AUTOSAR XML (schema 4-3-0)
package /PrmM_ArItf
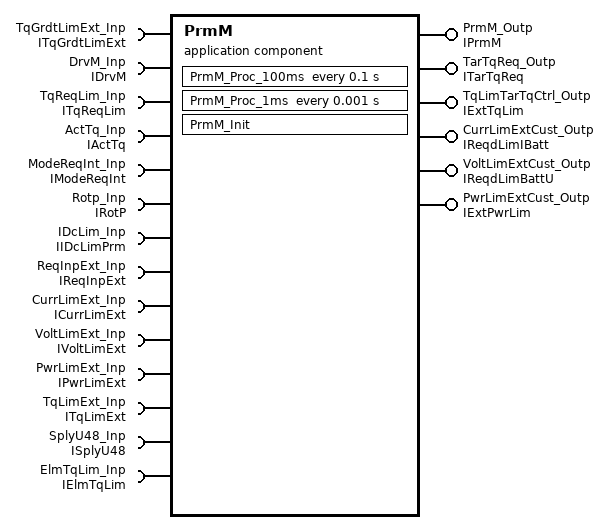
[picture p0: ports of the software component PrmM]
  application sw component type PrmM
    provide port PrmM_Outp: provided-interface=IPrmM
      provided-com-specs:
        data-element=uDcMinAllwd, init-value=24.0
        data-element=mMaxTqGrdtInt, init-value=0.1
        data-element=uDcMaxAllwd, init-value=24.0
    require port TqGrdtLimExt_Inp: nonqueued-receiver-com-spec{data-element=yTqGrdtLimExt, init-value=0}, required-interface=ITqGrdtLimExt
    require port DrvM_Inp: required-com-specs=[{data-element=sStateCAN, init-value=0}, {data-element=sState, init-value=0}], required-interface=IDrvM
    5 x provide port:
      TarTqReq_Outp: provided-interface=ITarTqReq
        provided-com-specs:
          data-element=mReqTqEM, init-value=0
          data-element=nReqdSpdEM, init-value=0
          data-element=uReqUEM, init-value=0
          data-element=xKpSpd, init-value=0
      TqLimTarTqCtrl_Outp: provided-com-specs=[{data-element=mTqLimMax, init-value=0}, {data-element=mTqLimMin, init-value=0}], provided-interface=IExtTqLim
      CurrLimExtCust_Outp: provided-com-specs=[{data-element=iReqdMaxBattI, init-value=0}, {data-element=iReqdMinBattI, init-value=0}], provided-interface=IReqdLimIBatt
      VoltLimExtCust_Outp: provided-com-specs=[{data-element=uReqdMaxBattU, init-value=0}, {data-element=uReqdMinBattU, init-value=0}], provided-interface=IReqdLimBattU
      PwrLimExtCust_Outp: provided-com-specs=[{data-element=pPwrMaxLim, init-value=0}, {data-element=pPwrMinLim, init-value=0}], provided-interface=IExtPwrLim
    12 x require port:
      TqReqLim_Inp: required-interface=ITqReqLim
        required-com-specs:
          data-element=ITqReqLim/mTqMax, init-value=0
          data-element=sStateTqRedn, init-value=0
          data-element=mTqReqLimd, init-value=0
          data-element=ITqReqLim/mTqMin, init-value=0
          data-element=mTqReqGrdtLimd, init-value=0
          data-element=mTqThermLimMin, init-value=0
          data-element=mTqThermLimMax, init-value=0
      ActTq_Inp: required-interface=IActTq
        required-com-specs:
          data-element=mTqActFild, init-value=0
          data-element=mTqDelta, init-value=0
          data-element=mTqAct, init-value=0
          data-element=mDragTq, init-value=0
      ModeReqInt_Inp: nonqueued-receiver-com-spec{data-element=sIntReqMode, init-value=CS_DrvM_STATE_Idle}, required-interface=IModeReqInt
      Rotp_Inp: required-interface=IRotP
        required-com-specs:
          data-element=xSinRaw, init-value=0
          data-element=xCosRaw, init-value=0
          data-element=nSpdMecl, init-value=0
          data-element=wPosnSnsr, init-value=0
          data-element=sStateRaw, init-value=0
          data-element=xSinCorr, init-value=0
          data-element=xCosCorr, init-value=0
          data-element=wPosnElec4, init-value=0
          data-element=wPosnElec3, init-value=0
          data-element=wPosnElec1, init-value=0
          data-element=wPosnElec2, init-value=0
          data-element=tTimestamp, init-value=0
          data-element=nSpdElec, init-value=0
      IDcLim_Inp: required-com-specs=[{data-element=IDcLimMaxInt, init-value=360}, {data-element=IDcLimMinInt, init-value=-290}], required-interface=IIDcLimPrm
      ReqInpExt_Inp: required-interface=IReqInpExt
        required-com-specs:
          data-element=uReqUEMExt, init-value=0
          data-element=mReqTqEMExt, init-value=0
          data-element=nReqSpdEMExt, init-value=0
      CurrLimExt_Inp: required-com-specs=[{data-element=iCurrMinLimExt, init-value=-290}, {data-element=iCurrMaxLimExt, init-value=360}], required-interface=ICurrLimExt
      VoltLimExt_Inp: required-com-specs=[{data-element=uVoltMaxLimExt, init-value=52}, {data-element=uVoltMinLimExt, init-value=24}], required-interface=IVoltLimExt
      PwrLimExt_Inp: required-com-specs=[{data-element=pPwrMInLimExt, init-value=-25000}, {data-element=pPwrMaxLimExt, init-value=25000}], required-interface=IPwrLimExt
      TqLimExt_Inp: required-com-specs=[{data-element=mTqLimMaxExt, init-value=40}, {data-element=mTqLimMinExt, init-value=0}], required-interface=ITqLimExt
      SplyU48_Inp: required-interface=ISplyU48
        required-com-specs:
          data-element=sUb48PlausStateRaw, init-value=0
          data-element=uUb48Ivs, init-value=0
          data-element=sUb48StateRaw, init-value=0
          data-element=uUb48Plaus, init-value=0
          data-element=uPhaseVoltLim, init-value=0
          data-element=uUb48, init-value=0
      ElmTqLim_Inp: required-interface=IElmTqLim
        required-com-specs:
          data-element=iIdqLenTqMax, init-value=0
          data-element=IElmTqLim/mTqMin, init-value=0
          data-element=iIdqLenTqMin, init-value=0
          data-element=IElmTqLim/mTqMax, init-value=0
    behavior PrmM_InternalBehavior: data-type-mapping=[Core_DTyps_DM_PrmM, PrmM_DTyps_DM_PrmM, DrvM_DTyps_DM_PrmM, TarTqC_DTyps_DM_PrmM, ElDern_DTyps_DM_PrmM, VoltLim_DTyps_DM_PrmM, PwrLim_DTyps_DM_PrmM, TqReqLim_DTyps_DM_PrmM, ActTq_DTyps_DM_PrmM, RotP_DTyps_DM_PrmM, ImplementationDataTypes_DM_PrmM, SplyU48_DTyps_DM_PrmM, ElmTqLim_DTyps_DM_PrmM], handle-termination-and-restart=NO-SUPPORT
      init event PrmM_InitEvent: start-on-event=PrmM_Init
      timing event TMT_PrmM_Proc_100ms: start-on-event=PrmM_Proc_100ms, period=0.1
      timing event TMT_PrmM_Proc_1ms: start-on-event=PrmM_Proc_1ms, period=0.001
      explicit-inter-runnable-variables:
        data uDcMin: type=AD_PrmM_tUDCMINALLWD, init-value=24.0
        data uDcMax: type=AD_PrmM_tUDCMAXALLWD, init-value=24.0
      runnable PrmM_Init
      runnable PrmM_Proc_100ms
        data-receive-point-by-arguments:
          access REC_DrvM_Inp_sState: accessed-variable=DrvM_Inp.sState
        written-local-variables:
          access WRITE_uDcMin: accessed-variable=uDcMin
          access WRITE_uDcMax: accessed-variable=uDcMax
      runnable PrmM_Proc_1ms
        data-receive-point-by-arguments:
          20 x access:
            REC_ActTq_Inp_mDragTq: accessed-variable=ActTq_Inp.mDragTq
            REC_TqLimExt_Inp_mTqLimMaxExt: accessed-variable=TqLimExt_Inp.mTqLimMaxExt
            REC_ElmTqLim_Inp_mTqMin: accessed-variable=ElmTqLim_Inp.mTqMin
            REC_TqReqLim_Inp_mTqMax: accessed-variable=TqReqLim_Inp.mTqMax
            REC_TqLimExt_Inp_mTqLimMinExt: accessed-variable=TqLimExt_Inp.mTqLimMinExt
            REC_TqGrdtLimExt_Inp_yTqGrdtLimExt: accessed-variable=TqGrdtLimExt_Inp.yTqGrdtLimExt
            REC_Rotp_Inp_nSpdMecl: accessed-variable=Rotp_Inp.nSpdMecl
            REC_TqReqLim_Inp_mTqMin: accessed-variable=TqReqLim_Inp.mTqMin
            REC_DrvM_Inp_sState: accessed-variable=DrvM_Inp.sState
            REC_SplyU48_Inp_uUb48: accessed-variable=SplyU48_Inp.uUb48
            REC_ModeReqInt_Inp_sIntReqMode: accessed-variable=ModeReqInt_Inp.sIntReqMode
            REC_ReqInpExt_Inp_mReqTqEMExt: accessed-variable=ReqInpExt_Inp.mReqTqEMExt
            REC_ReqInpExt_Inp_uReqUEMExt: accessed-variable=ReqInpExt_Inp.uReqUEMExt
            REC_ReqInpExt_Inp_nReqSpdEMExt: accessed-variable=ReqInpExt_Inp.nReqSpdEMExt
            REC_CurrLimExt_Inp_iCurrMinLimExt: accessed-variable=CurrLimExt_Inp.iCurrMinLimExt
            REC_VoltLimExt_Inp_uVoltMaxLimExt: accessed-variable=VoltLimExt_Inp.uVoltMaxLimExt
            REC_PwrLimExt_Inp_pPwrMInLimExt: accessed-variable=PwrLimExt_Inp.pPwrMInLimExt
            REC_CurrLimExt_Inp_iCurrMaxLimExt: accessed-variable=CurrLimExt_Inp.iCurrMaxLimExt
            REC_PwrLimExt_Inp_pPwrMaxLimExt: accessed-variable=PwrLimExt_Inp.pPwrMaxLimExt
            REC_VoltLimExt_Inp_uVoltMinLimExt: accessed-variable=VoltLimExt_Inp.uVoltMinLimExt
        data-send-points:
          11 x access:
            SEND_TqLimTarTqCtrl_Outp_mTqLimMin: accessed-variable=TqLimTarTqCtrl_Outp.mTqLimMin
            SEND_TqLimTarTqCtrl_Outp_mTqLimMax: accessed-variable=TqLimTarTqCtrl_Outp.mTqLimMax
            SEND_TarTqReq_Outp_nReqdSpdEM: accessed-variable=TarTqReq_Outp.nReqdSpdEM
            SEND_TarTqReq_Outp_uReqUEM: accessed-variable=TarTqReq_Outp.uReqUEM
            SEND_TarTqReq_Outp_mReqTqEM: accessed-variable=TarTqReq_Outp.mReqTqEM
            SEND_VoltLimExtCust_Outp_uReqdMinBattU: accessed-variable=VoltLimExtCust_Outp.uReqdMinBattU
            SEND_CurrLimExtCust_Outp_iReqdMinBattI: accessed-variable=CurrLimExtCust_Outp.iReqdMinBattI
            SEND_CurrLimExtCust_Outp_iReqdMaxBattI: accessed-variable=CurrLimExtCust_Outp.iReqdMaxBattI
            SEND_PwrLimExtCust_Outp_pPwrMinLim: accessed-variable=PwrLimExtCust_Outp.pPwrMinLim
            SEND_VoltLimExtCust_Outp_uReqdMaxBattU: accessed-variable=VoltLimExtCust_Outp.uReqdMaxBattU
            SEND_PwrLimExtCust_Outp_pPwrMaxLim: accessed-variable=PwrLimExtCust_Outp.pPwrMaxLim
        read-local-variables:
          access READ_uDcMax: accessed-variable=uDcMax
          access READ_uDcMin: accessed-variable=uDcMin
  6 x sender receiver interface:
    ITqGrdtLimExt: invalidation-policy{data-element=yTqGrdtLimExt, handle-invalid=DONT-INVALIDATE}
      data yTqGrdtLimExt: type=AD_tYTQGRDTLIMEXT
    IReqInpExt
      data mReqTqEMExt: type=AD_tMREQTQEMEXT
      data nReqSpdEMExt: type=AD_tNREQDSPDEMEXT
      data uReqUEMExt: type=AD_tUREQVOLTEMEXT
      invalidation-policys:
        data-element=mReqTqEMExt, handle-invalid=DONT-INVALIDATE
        data-element=nReqSpdEMExt, handle-invalid=DONT-INVALIDATE
        data-element=uReqUEMExt, handle-invalid=DONT-INVALIDATE
    ICurrLimExt
      data iCurrMinLimExt: type=AD_tICURRMINLIMEXT
      data iCurrMaxLimExt: type=AD_tICURRMAXLIMEXT
      invalidation-policys:
        data-element=iCurrMinLimExt, handle-invalid=DONT-INVALIDATE
        data-element=iCurrMaxLimExt, handle-invalid=DONT-INVALIDATE
    IVoltLimExt
      data uVoltMinLimExt: type=AD_tUVOLTMINLIMEXT
      data uVoltMaxLimExt: type=AD_tUVOLTMAXLIMEXT
      invalidation-policys:
        data-element=uVoltMinLimExt, handle-invalid=DONT-INVALIDATE
        data-element=uVoltMaxLimExt, handle-invalid=DONT-INVALIDATE
    IPwrLimExt
      data pPwrMaxLimExt: type=AD_tPPWRMAXLIMEXT
      data pPwrMInLimExt: type=AD_tPPWRMINLIMEXT
      invalidation-policys:
        data-element=pPwrMaxLimExt, handle-invalid=DONT-INVALIDATE
        data-element=pPwrMInLimExt, handle-invalid=DONT-INVALIDATE
    ITqLimExt
      data mTqLimMaxExt: type=AD_tMTQLIMMAXEXT
      data mTqLimMinExt: type=AD_tMTQLIMMINEXT
      invalidation-policys:
        data-element=mTqLimMaxExt, handle-invalid=DONT-INVALIDATE
        data-element=mTqLimMinExt, handle-invalid=DONT-INVALIDATE
  swc implementation PrmM_Implementation: behavior=PrmM_InternalBehavior
    code-descriptors:
      code Default: artifact-descriptors=autosar-engineering-object={short-label=Default, category=SWSRC}
package /PrmM_ArItf/PrmM_DTyps
  app type AD_tYTQGRDTLIMEXT: category=VALUE, range phys 0..2000  # Unit: Nm/s
  data type mapping set PrmM_DTyps_DM_PrmM
    data-type-maps:
      application-data-type=AD_tYTQGRDTLIMEXT, implementation-data-type=float32
      application-data-type=AD_tMREQTQEMEXT, implementation-data-type=float32
      application-data-type=AD_tNREQDSPDEMEXT, implementation-data-type=float32
      application-data-type=AD_tUREQVOLTEMEXT, implementation-data-type=float32
      application-data-type=AD_tICURRMINLIMEXT, implementation-data-type=float32
      application-data-type=AD_tICURRMAXLIMEXT, implementation-data-type=float32
      application-data-type=AD_tUVOLTMINLIMEXT, implementation-data-type=float32
      application-data-type=AD_tUVOLTMAXLIMEXT, implementation-data-type=float32
      application-data-type=AD_tPPWRMAXLIMEXT, implementation-data-type=float32
      application-data-type=AD_tPPWRMINLIMEXT, implementation-data-type=float32
      application-data-type=AD_tMTQLIMMAXEXT, implementation-data-type=float32
      application-data-type=AD_tMTQLIMMINEXT, implementation-data-type=float32
  app type AD_tMREQTQEMEXT: category=VALUE, range phys -75..75
  app type AD_tNREQDSPDEMEXT: category=VALUE, range phys -10000..55534
  app type AD_tUREQVOLTEMEXT: category=VALUE, range phys 0..60
  app type AD_tICURRMINLIMEXT: category=VALUE, range phys -1200..1200
  app type AD_tICURRMAXLIMEXT: category=VALUE, range phys -1200..1200
  app type AD_tUVOLTMINLIMEXT: category=VALUE, range phys 20..65
  app type AD_tUVOLTMAXLIMEXT: category=VALUE, range phys 20..65
  app type AD_tPPWRMAXLIMEXT: category=VALUE, range phys -16000..16000
  app type AD_tPPWRMINLIMEXT: category=VALUE, range phys -16000..16000
  app type AD_tMTQLIMMAXEXT: category=VALUE, range phys 0..65
  app type AD_tMTQLIMMINEXT: category=VALUE, range phys -65..0
package /ComponentTypes
  sender receiver interface IPrmM
    data uDcMinAllwd: type=AD_PrmM_tUDCMINALLWD
    data uDcMaxAllwd: type=AD_PrmM_tUDCMAXALLWD
    data mMaxTqGrdtInt: type=AD_PrmM_tMMAXTQGRDINT
    invalidation-policys:
      data-element=uDcMinAllwd, handle-invalid=DONT-INVALIDATE
      data-element=uDcMaxAllwd, handle-invalid=DONT-INVALIDATE
      data-element=mMaxTqGrdtInt, handle-invalid=DONT-INVALIDATE
  sender receiver interface IIDcLimPrm
    data IDcLimMinInt: type=AD_tIDCLIMMININT
    data IDcLimMaxInt: type=AD_tIDCLIMMAXINT
    invalidation-policys:
      data-element=IDcLimMinInt, handle-invalid=DONT-INVALIDATE
      data-element=IDcLimMaxInt, handle-invalid=DONT-INVALIDATE
package /ComponentTypes/Core_DTyps
  app type AD_PrmM_tUDCMINALLWD: category=VALUE, range phys 20..65
  data type mapping set Core_DTyps_DM_PrmM
    data-type-maps:
      application-data-type=AD_PrmM_tUDCMINALLWD, implementation-data-type=float32
      application-data-type=AD_PrmM_tUDCMAXALLWD, implementation-data-type=float32
      application-data-type=AD_PrmM_tMMAXTQGRDINT, implementation-data-type=float32
      application-data-type=AD_tIDCLIMMININT, implementation-data-type=float32
      application-data-type=AD_tIDCLIMMAXINT, implementation-data-type=float32
  app type AD_PrmM_tUDCMAXALLWD: category=VALUE, range phys 20..65
  app type AD_PrmM_tMMAXTQGRDINT: category=VALUE, range phys 0.1..2000
  app type AD_tIDCLIMMININT: category=VALUE, range phys -400..0
  app type AD_tIDCLIMMAXINT: category=VALUE, range phys 0..400
package /DrvM_ArItf
  sender receiver interface IDrvM
    data sState: type=AD_DrvM_tSTATEIDX_E
    data sStateCAN: type=AD_DrvM_tSTATEIDX_E
    invalidation-policys:
      data-element=sState, handle-invalid=DONT-INVALIDATE
      data-element=sStateCAN, handle-invalid=DONT-INVALIDATE
  sender receiver interface IModeReqInt: invalidation-policy{data-element=sIntReqMode, handle-invalid=DONT-INVALIDATE}
    data sIntReqMode: type=AD_DrvM_tSTATEIDX_E
package /DrvM_ArItf/DrvM_DTyps
  compu method CM_DrvM_AD_DrvM_tSTATEIDX_E: 0=CS_DrvM_STATE_Idle, 3=CS_DrvM_STATE_Volt, 5=CS_DrvM_STATE_BattDiscnctd
  app type AD_DrvM_tSTATEIDX_E: category=VALUE, compu-method=CM_DrvM_AD_DrvM_tSTATEIDX_E, range raw 0..255
  impl type CS_DrvM_tSTATEIDX_E: compu-method=CM_DrvM_AD_DrvM_tSTATEIDX_E, implementation-data-type=uint8
  data type mapping set DrvM_DTyps_DM_PrmM: data-type-map{application-data-type=AD_DrvM_tSTATEIDX_E, implementation-data-type=CS_DrvM_tSTATEIDX_E}
package /TarTqC_ArItf
  sender receiver interface ITarTqReq
    4 x data:
      uReqUEM: type=AD_ComWrp_tUREQVOLTEM
      mReqTqEM: type=AD_ComWrp_tMREQTQEM
      nReqdSpdEM: type=AD_ComWrp_tNREQDSPDEM
      xKpSpd: type=AD_ComWrp_tXKPSPD
    invalidation-policys:
      data-element=uReqUEM, handle-invalid=DONT-INVALIDATE
      data-element=mReqTqEM, handle-invalid=DONT-INVALIDATE
      data-element=nReqdSpdEM, handle-invalid=DONT-INVALIDATE
      data-element=xKpSpd, handle-invalid=DONT-INVALIDATE
  sender receiver interface IExtTqLim
    data mTqLimMax: type=AD_ComWrp_tMTQLIMMAX
    data mTqLimMin: type=AD_ComWrp_tMTQLIMMIN
    invalidation-policys:
      data-element=mTqLimMax, handle-invalid=DONT-INVALIDATE
      data-element=mTqLimMin, handle-invalid=DONT-INVALIDATE
package /TarTqC_ArItf/TarTqC_DTyps
  app type AD_ComWrp_tUREQVOLTEM: category=VALUE, range phys 0..60
  data type mapping set TarTqC_DTyps_DM_PrmM
    data-type-maps:
      application-data-type=AD_ComWrp_tUREQVOLTEM, implementation-data-type=float32
      application-data-type=AD_ComWrp_tMREQTQEM, implementation-data-type=float32
      application-data-type=AD_ComWrp_tNREQDSPDEM, implementation-data-type=float32
      application-data-type=AD_ComWrp_tXKPSPD, implementation-data-type=float32
      application-data-type=AD_ComWrp_tMTQLIMMAX, implementation-data-type=float32
      application-data-type=AD_ComWrp_tMTQLIMMIN, implementation-data-type=float32
  app type AD_ComWrp_tMREQTQEM: category=VALUE, range phys -75..75
  app type AD_ComWrp_tNREQDSPDEM: category=VALUE, range phys -10000..55534
  app type AD_ComWrp_tXKPSPD: category=VALUE, range phys -4..3.984375
  app type AD_ComWrp_tMTQLIMMAX: category=VALUE, range phys -75..75
  app type AD_ComWrp_tMTQLIMMIN: category=VALUE, range phys -75..75
package /ElDern_ArItf
  sender receiver interface IReqdLimIBatt
    data iReqdMinBattI: type=AD_ComWrp_tIREQDMINBATTI
    data iReqdMaxBattI: type=AD_ComWrp_tIREQDMAXBATTI
    invalidation-policys:
      data-element=iReqdMinBattI, handle-invalid=DONT-INVALIDATE
      data-element=iReqdMaxBattI, handle-invalid=DONT-INVALIDATE
package /ElDern_ArItf/ElDern_DTyps
  app type AD_ComWrp_tIREQDMINBATTI: category=VALUE, range phys -1200..1200
  data type mapping set ElDern_DTyps_DM_PrmM
    data-type-maps:
      application-data-type=AD_ComWrp_tIREQDMINBATTI, implementation-data-type=float32
      application-data-type=AD_ComWrp_tIREQDMAXBATTI, implementation-data-type=float32
  app type AD_ComWrp_tIREQDMAXBATTI: category=VALUE, range phys -1200..1200
package /VoltLim_ArItf
  sender receiver interface IReqdLimBattU
    data uReqdMinBattU: type=AD_ComWrp_tUREQDMINBATTU
    data uReqdMaxBattU: type=AD_ComWrp_tUREQDMAXBATTU
    invalidation-policys:
      data-element=uReqdMinBattU, handle-invalid=DONT-INVALIDATE
      data-element=uReqdMaxBattU, handle-invalid=DONT-INVALIDATE
package /VoltLim_ArItf/VoltLim_DTyps
  app type AD_ComWrp_tUREQDMINBATTU: category=VALUE, range phys 0..2500
  data type mapping set VoltLim_DTyps_DM_PrmM
    data-type-maps:
      application-data-type=AD_ComWrp_tUREQDMINBATTU, implementation-data-type=float32
      application-data-type=AD_ComWrp_tUREQDMAXBATTU, implementation-data-type=float32
  app type AD_ComWrp_tUREQDMAXBATTU: category=VALUE, range phys 0..2500
package /PwrLim_ArItf
  sender receiver interface IExtPwrLim
    data pPwrMaxLim: type=AD_ComWrp_tPPWRMAXLIM
    data pPwrMinLim: type=AD_ComWrp_tPPWRMINLIM
    invalidation-policys:
      data-element=pPwrMaxLim, handle-invalid=DONT-INVALIDATE
      data-element=pPwrMinLim, handle-invalid=DONT-INVALIDATE
package /PwrLim_ArItf/PwrLim_DTyps
  app type AD_ComWrp_tPPWRMAXLIM: category=VALUE, range phys -819000..819200
  data type mapping set PwrLim_DTyps_DM_PrmM
    data-type-maps:
      application-data-type=AD_ComWrp_tPPWRMAXLIM, implementation-data-type=float32
      application-data-type=AD_ComWrp_tPPWRMINLIM, implementation-data-type=float32
  app type AD_ComWrp_tPPWRMINLIM: category=VALUE, range phys -819000..819200
package /TqReqLim_ArItf
  sender receiver interface ITqReqLim
    7 x data:
      mTqThermLimMax: type=AD_TqReqLim_tTQTHERMLIMMAX
      mTqMax: type=AD_TqReqLim_tMTQMAX
      mTqReqGrdtLimd: type=AD_TqReqLim_tMTQGRDLIMD
      mTqMin: type=AD_TqReqLim_tMTQMIN
      mTqThermLimMin: type=AD_TqReqLim_tTQTHERMLIMMIN
      sStateTqRedn: type=AD_TqReqLim_tSTATETQREDN_E
      mTqReqLimd: type=AD_TqReqLim_tMTQLIMD
    invalidation-policys:
      data-element=mTqThermLimMax, handle-invalid=DONT-INVALIDATE
      data-element=ITqReqLim/mTqMax, handle-invalid=DONT-INVALIDATE
      data-element=mTqReqGrdtLimd, handle-invalid=DONT-INVALIDATE
      data-element=ITqReqLim/mTqMin, handle-invalid=DONT-INVALIDATE
      data-element=mTqThermLimMin, handle-invalid=DONT-INVALIDATE
      data-element=sStateTqRedn, handle-invalid=DONT-INVALIDATE
      data-element=mTqReqLimd, handle-invalid=DONT-INVALIDATE
package /TqReqLim_ArItf/TqReqLim_DTyps
  app type AD_TqReqLim_tTQTHERMLIMMAX: category=VALUE, range phys 0..85
  data type mapping set TqReqLim_DTyps_DM_PrmM
    data-type-maps:
      application-data-type=AD_TqReqLim_tTQTHERMLIMMAX, implementation-data-type=float32
      application-data-type=AD_TqReqLim_tMTQMAX, implementation-data-type=float32
      application-data-type=AD_TqReqLim_tMTQGRDLIMD, implementation-data-type=float32
      application-data-type=AD_TqReqLim_tMTQMIN, implementation-data-type=float32
      application-data-type=AD_TqReqLim_tTQTHERMLIMMIN, implementation-data-type=float32
      application-data-type=AD_TqReqLim_tSTATETQREDN_E, implementation-data-type=CS_TqReqLim_tSTATETQREDN_E
      application-data-type=AD_TqReqLim_tMTQLIMD, implementation-data-type=float32
  app type AD_TqReqLim_tMTQMAX: category=VALUE, range phys -85..85
  app type AD_TqReqLim_tMTQGRDLIMD: category=VALUE, range phys -85..85
  app type AD_TqReqLim_tMTQMIN: category=VALUE, range phys -85..85
  app type AD_TqReqLim_tTQTHERMLIMMIN: category=VALUE, range phys -85..0
  compu method CM_TqReqLim_AD_TqReqLim_tSTATETQREDN_E: 0=CS_TqReqLim_STATE_TQ_REDN_InActv, 1=CS_TqReqLim_STATE_TQ_REDN_BattVoltLimn, 2=CS_TqReqLim_STATE_TQ_REDN_BattCurrLimn, 3=CS_TqReqLim_STATE_TQ_REDN_uC, 4=CS_TqReqLim_STATE_TQ_REDN_Fet, 5=CS_TqReqLim_STATE_TQ_REDN_Logic, 6=CS_TqReqLim_STATE_TQ_REDN_PowerPcb, 7=CS_TqReqLim_STATE_TQ_REDN_Coil, 8=CS_TqReqLim_STATE_TQ_REDN_StatorCu, 9=CS_TqReqLim_STATE_TQ_REDN_StatorFe, 10=CS_TqReqLim_STATE_TQ_REDN_RotorCu, 11=CS_TqReqLim_STATE_TQ_REDN_RotorMag, 12=CS_TqReqLim_STATE_TQ_REDN_CstLimn, 13=CS_TqReqLim_STATE_TQ_REDN_PwrMdlNTC, 14=CS_TqReqLim_STATE_TQ_REDN_TqRateLimn, 15=CS_TqReqLim_STATE_TQ_REDN_ElmTqLimn, 16=CS_TqReqLim_STATE_TQ_REDN_LutTqLimn, 17=CS_TqReqLim_STATE_TQ_REDN_CstTqLimn
  app type AD_TqReqLim_tSTATETQREDN_E: category=VALUE, compu-method=CM_TqReqLim_AD_TqReqLim_tSTATETQREDN_E, range raw 0..18
  impl type CS_TqReqLim_tSTATETQREDN_E: compu-method=CM_TqReqLim_AD_TqReqLim_tSTATETQREDN_E, implementation-data-type=uint8
  app type AD_TqReqLim_tMTQLIMD: category=VALUE, range phys -85..85
package /ActTq_ArItf
  sender receiver interface IActTq
    4 x data:
      mTqActFild: type=AD_ActTq_tMTQACTFILD
      mTqDelta: type=AD_ActTq_tMTQDELTA
      mTqAct: type=AD_ActTq_tMTQACT
      mDragTq: type=AD_ActTq_tMDRAGTQ
    invalidation-policys:
      data-element=mTqActFild, handle-invalid=DONT-INVALIDATE
      data-element=mTqDelta, handle-invalid=DONT-INVALIDATE
      data-element=mTqAct, handle-invalid=DONT-INVALIDATE
      data-element=mDragTq, handle-invalid=DONT-INVALIDATE
package /ActTq_ArItf/ActTq_DTyps
  app type AD_ActTq_tMTQACTFILD: category=VALUE, range phys -85..85
  data type mapping set ActTq_DTyps_DM_PrmM
    data-type-maps:
      application-data-type=AD_ActTq_tMTQACTFILD, implementation-data-type=float32
      application-data-type=AD_ActTq_tMTQDELTA, implementation-data-type=float32
      application-data-type=AD_ActTq_tMTQACT, implementation-data-type=float32
      application-data-type=AD_ActTq_tMDRAGTQ, implementation-data-type=float32
  app type AD_ActTq_tMTQDELTA: category=VALUE, range phys -85..85
  app type AD_ActTq_tMTQACT: category=VALUE, range phys -85..85
  app type AD_ActTq_tMDRAGTQ: category=VALUE, range phys -85..85
package /RotP_ArItf
  sender receiver interface IRotP
    13 x data:
      xSinCorr: type=AD_RotP_tXSINCORR
      xSinRaw: type=AD_RotP_tXSINRAW
      nSpdMecl: type=AD_RotP_tNSPDMECL
      wPosnSnsr: type=AD_RotP_tWPOSNSNSR
      wPosnElec1: type=AD_RotP_tWPOSNELEC
      wPosnElec4: type=AD_RotP_tWPOSNELEC
      xCosRaw: type=AD_RotP_tXCOSRAW
      wPosnElec3: type=AD_RotP_tWPOSNELEC
      sStateRaw: type=AD_StdT_tSENSORSTATE_E
      xCosCorr: type=AD_RotP_tXCOSCORR
      wPosnElec2: type=AD_RotP_tWPOSNELEC
      tTimestamp: type=AD_RotP_tTTIMESTAMP
      nSpdElec: type=AD_RotP_tNSPDELEC
    invalidation-policys:
      data-element=xSinCorr, handle-invalid=DONT-INVALIDATE
      data-element=xSinRaw, handle-invalid=DONT-INVALIDATE
      data-element=nSpdMecl, handle-invalid=DONT-INVALIDATE
      data-element=wPosnSnsr, handle-invalid=DONT-INVALIDATE
      data-element=wPosnElec1, handle-invalid=DONT-INVALIDATE
      data-element=wPosnElec4, handle-invalid=DONT-INVALIDATE
      data-element=xCosRaw, handle-invalid=DONT-INVALIDATE
      data-element=wPosnElec3, handle-invalid=DONT-INVALIDATE
      data-element=sStateRaw, handle-invalid=DONT-INVALIDATE
      data-element=xCosCorr, handle-invalid=DONT-INVALIDATE
      data-element=wPosnElec2, handle-invalid=DONT-INVALIDATE
      data-element=tTimestamp, handle-invalid=DONT-INVALIDATE
      data-element=nSpdElec, handle-invalid=DONT-INVALIDATE
package /RotP_ArItf/RotP_DTyps
  app type AD_RotP_tXSINCORR: category=VALUE, range phys -1.5..1.5
  data type mapping set RotP_DTyps_DM_PrmM
    data-type-maps:
      application-data-type=AD_RotP_tXSINCORR, implementation-data-type=float32
      application-data-type=AD_RotP_tXSINRAW, implementation-data-type=float32
      application-data-type=AD_RotP_tNSPDMECL, implementation-data-type=float32
      application-data-type=AD_RotP_tWPOSNSNSR, implementation-data-type=float32
      application-data-type=AD_RotP_tWPOSNELEC, implementation-data-type=float32
      application-data-type=AD_RotP_tXCOSRAW, implementation-data-type=float32
      application-data-type=AD_RotP_tXCOSCORR, implementation-data-type=float32
      application-data-type=AD_RotP_tTTIMESTAMP, implementation-data-type=uint32
      application-data-type=AD_RotP_tNSPDELEC, implementation-data-type=float32
  app type AD_RotP_tXSINRAW: category=VALUE, range phys -1.5..1.5
  app type AD_RotP_tNSPDMECL: category=VALUE, range phys -22000..22000
  app type AD_RotP_tWPOSNSNSR: category=VALUE, range phys -3.1416..3.1416
  app type AD_RotP_tWPOSNELEC: category=VALUE, range phys -3.1416..3.1416
  app type AD_RotP_tXCOSRAW: category=VALUE, range phys -1.5..1.5
  app type AD_RotP_tXCOSCORR: category=VALUE, range phys -1.5..1.5
  app type AD_RotP_tTTIMESTAMP: category=VALUE, range phys 0..4294967295
  app type AD_RotP_tNSPDELEC: category=VALUE, range phys -18435..18435
package /AUTOSAR_Platform/ImplementationDataTypes
  app type AD_StdT_tSENSORSTATE_E: category=VALUE, compu {0=CS_StdT_tSENSORSTATE_Valid, 1=CS_StdT_tSENSORSTATE_Invalid}, range raw 0..1
  impl type CS_StdT_tSENSORSTATE_E: compu {0=CS_StdT_tSENSORSTATE_Valid, 1=CS_StdT_tSENSORSTATE_Invalid}, implementation-data-type=uint8
  data type mapping set ImplementationDataTypes_DM_PrmM: data-type-map{application-data-type=AD_StdT_tSENSORSTATE_E, implementation-data-type=CS_StdT_tSENSORSTATE_E}
package /SplyU48_ArItf
  sender receiver interface ISplyU48
    6 x data:
      uUb48: type=AD_SplyU_tUUB48
      uUb48Plaus: type=AD_SplyU_tUUB48PLAUS
      uUb48Ivs: type=AD_SplyU_tUUB48IVS
      sUb48StateRaw: type=AD_StdT_tSENSORSTATE_E
      uPhaseVoltLim: type=AD_SplyU_tUPHASEVOLTLIM
      sUb48PlausStateRaw: type=AD_StdT_tSENSORSTATE_E
    invalidation-policys:
      data-element=uUb48, handle-invalid=DONT-INVALIDATE
      data-element=uUb48Plaus, handle-invalid=DONT-INVALIDATE
      data-element=uUb48Ivs, handle-invalid=DONT-INVALIDATE
      data-element=sUb48StateRaw, handle-invalid=DONT-INVALIDATE
      data-element=uPhaseVoltLim, handle-invalid=DONT-INVALIDATE
      data-element=sUb48PlausStateRaw, handle-invalid=DONT-INVALIDATE
package /SplyU48_ArItf/SplyU48_DTyps
  app type AD_SplyU_tUUB48: category=VALUE, range phys 0..80
  data type mapping set SplyU48_DTyps_DM_PrmM
    data-type-maps:
      application-data-type=AD_SplyU_tUUB48, implementation-data-type=float32
      application-data-type=AD_SplyU_tUUB48PLAUS, implementation-data-type=float32
      application-data-type=AD_SplyU_tUUB48IVS, implementation-data-type=float32
      application-data-type=AD_SplyU_tUPHASEVOLTLIM, implementation-data-type=float32
  app type AD_SplyU_tUUB48PLAUS: category=VALUE, range phys 0..80
  app type AD_SplyU_tUUB48IVS: category=VALUE, range phys 0..10
  app type AD_SplyU_tUPHASEVOLTLIM: category=VALUE, range phys 0..50.9296
package /ElmTqLim_ArItf
  sender receiver interface IElmTqLim
    4 x data:
      iIdqLenTqMax: type=AD_ElmTqLim_tIIDQLENTQMAX
      mTqMax: type=AD_ElmTqLim_tMTQMAX
      iIdqLenTqMin: type=AD_ElmTqLim_tIIDQLENTQMIN
      mTqMin: type=AD_ElmTqLim_tMTQMIN
    invalidation-policys:
      data-element=iIdqLenTqMax, handle-invalid=DONT-INVALIDATE
      data-element=IElmTqLim/mTqMax, handle-invalid=DONT-INVALIDATE
      data-element=iIdqLenTqMin, handle-invalid=DONT-INVALIDATE
      data-element=IElmTqLim/mTqMin, handle-invalid=DONT-INVALIDATE
package /ElmTqLim_ArItf/ElmTqLim_DTyps
  app type AD_ElmTqLim_tIIDQLENTQMAX: category=VALUE, range phys 0..400
  data type mapping set ElmTqLim_DTyps_DM_PrmM
    data-type-maps:
      application-data-type=AD_ElmTqLim_tIIDQLENTQMAX, implementation-data-type=float32
      application-data-type=AD_ElmTqLim_tMTQMAX, implementation-data-type=float32
      application-data-type=AD_ElmTqLim_tIIDQLENTQMIN, implementation-data-type=float32
      application-data-type=AD_ElmTqLim_tMTQMIN, implementation-data-type=float32
  app type AD_ElmTqLim_tMTQMAX: category=VALUE, range phys 0..85
  app type AD_ElmTqLim_tIIDQLENTQMIN: category=VALUE, range phys 0..400
  app type AD_ElmTqLim_tMTQMIN: category=VALUE, range phys -85..0
